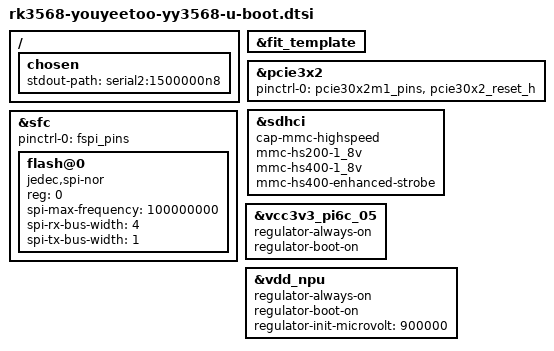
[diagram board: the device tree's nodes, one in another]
// SPDX-License-Identifier: (GPL-2.0+ OR MIT)

#include "rk356x-u-boot.dtsi"

/ {
	chosen {
		stdout-path = "serial2:1500000n8";
	};
};

/* The rk chainloader rejects data-position/data-offset external FITs. */
&fit_template {
	/delete-property/ fit,external-offset;
};

&pcie3x2 {
	pinctrl-0 = <&pcie30x2m1_pins &pcie30x2_reset_h>;
};

&sdhci {
	cap-mmc-highspeed;
	mmc-hs200-1_8v;
	mmc-hs400-1_8v;
	mmc-hs400-enhanced-strobe;
};

&sfc {
	#address-cells = <1>;
	#size-cells = <0>;
	pinctrl-names = "default";
	pinctrl-0 = <&fspi_pins>;
	status = "okay";

	flash@0 {
		bootph-pre-ram;
		bootph-some-ram;
		compatible = "jedec,spi-nor";
		reg = <0>;
		spi-max-frequency = <100000000>;
		spi-rx-bus-width = <4>;
		spi-tx-bus-width = <1>;
	};
};

&vcc3v3_pi6c_05 {
	regulator-always-on;
	regulator-boot-on;
};

/* Required by the Rockchip 6.1 BSP NPU power-domain handoff. */
&vdd_npu {
	regulator-always-on;
	regulator-boot-on;
	regulator-init-microvolt = <900000>;
};
